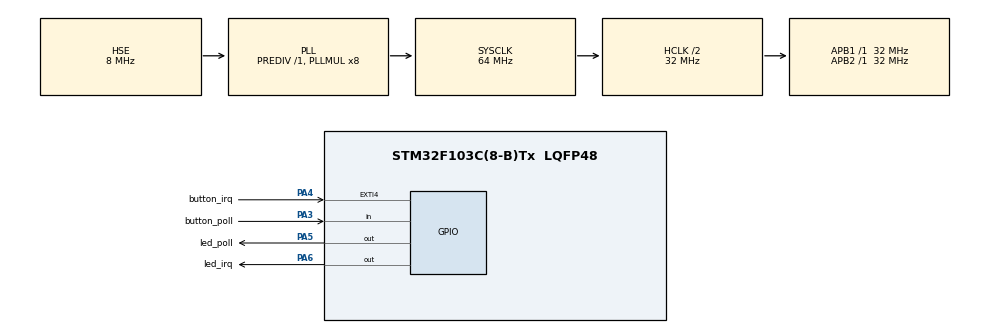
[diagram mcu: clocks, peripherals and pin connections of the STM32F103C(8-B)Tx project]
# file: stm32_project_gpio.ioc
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Mcu.Family=STM32F1
Mcu.Name=STM32F103C(8-B)Tx
Mcu.Package=LQFP48
NVIC.EXTI4_IRQn=true\:0\:0\:false\:false\:true\:true\:true
NVIC.PriorityGroup=NVIC_PRIORITYGROUP_4
PA13.Mode=Serial_Wire
PA13.Signal=SYS_JTMS-SWDIO
PA14.Mode=Serial_Wire
PA14.Signal=SYS_JTCK-SWCLK
PA3.GPIO_Label=button_poll
PA3.Signal=GPIO_Input
PA4.GPIO_Label=button_irq
PA4.GPIO_ModeDefaultEXTI=GPIO_MODE_IT_FALLING
PA4.Signal=GPXTI4
PA5.GPIO_Label=led_poll
PA5.Signal=GPIO_Output
PA6.GPIO_Label=led_irq
PA6.Signal=GPIO_Output
PD0-OSC_IN.Mode=HSE-External-Oscillator
PD0-OSC_IN.Signal=RCC_OSC_IN
PD1-OSC_OUT.Mode=HSE-External-Oscillator
PD1-OSC_OUT.Signal=RCC_OSC_OUT
ProjectManager.HeapSize=0x200
ProjectManager.StackSize=0x400
ProjectManager.TargetToolchain=Makefile
RCC.AHBCLKDivider=RCC_SYSCLK_DIV2
RCC.AHBFreq_Value=32000000
RCC.APB1Freq_Value=32000000
RCC.APB1TimFreq_Value=32000000
RCC.APB2Freq_Value=32000000
RCC.APB2TimFreq_Value=32000000
RCC.HCLKFreq_Value=32000000
RCC.PLLMUL=RCC_PLL_MUL8
RCC.PLLSourceVirtual=RCC_PLLSOURCE_HSE
RCC.SYSCLKFreq_VALUE=64000000
RCC.SYSCLKSource=RCC_SYSCLKSOURCE_PLLCLK
RCC.USBFreq_Value=64000000
board=custom

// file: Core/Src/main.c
/* USER CODE BEGIN Header */
/**
  ******************************************************************************
  * @file           : main.c
  * @brief          : Main program body
  ******************************************************************************
  * @attention
  *
  * <h2><center>&copy; Copyright (c) 2023 STMicroelectronics.
  * All rights reserved.</center></h2>
  *
  * This software component is licensed by ST under BSD 3-Clause license,
  * the "License"; You may not use this file except in compliance with the
  * License. You may obtain a copy of the License at:
  *                        opensource.org/licenses/BSD-3-Clause
  *
  ******************************************************************************
  */
/* USER CODE END Header */
#include "main.h"

void SystemClock_Config(void);
static void MX_GPIO_Init(void);

/* USER CODE BEGIN 0 */
int interrupted;
/* USER CODE END 0 */

int main(void)
{

  /* MCU Configuration--------------------------------------------------------*/

  /* Reset of all peripherals, Initializes the Flash interface and the Systick. */
  HAL_Init();

  /* Configure the system clock */
  SystemClock_Config();

  /* Initialize all configured peripherals */
  MX_GPIO_Init();

  /* Infinite loop */
  /* USER CODE BEGIN WHILE */
  interrupted = 0;
  while (1)
  {
    GPIO_PinState state = HAL_GPIO_ReadPin(button_poll_GPIO_Port, button_poll_Pin);
    HAL_GPIO_WritePin(led_poll_GPIO_Port, led_poll_Pin, state);

    if (interrupted) {
      interrupted = 0;
      HAL_NVIC_EnableIRQ(EXTI4_IRQn);
      HAL_GPIO_TogglePin(led_irq_GPIO_Port, led_irq_Pin);
    }
    /* USER CODE END WHILE */

  }
}

void SystemClock_Config(void)
{
  RCC_OscInitTypeDef RCC_OscInitStruct = {0};
  RCC_ClkInitTypeDef RCC_ClkInitStruct = {0};

  /** Initializes the RCC Oscillators according to the specified parameters
  * in the RCC_OscInitTypeDef structure.
  */
  RCC_OscInitStruct.OscillatorType = RCC_OSCILLATORTYPE_HSE;
  RCC_OscInitStruct.HSEState = RCC_HSE_ON;
  RCC_OscInitStruct.HSEPredivValue = RCC_HSE_PREDIV_DIV1;
  RCC_OscInitStruct.HSIState = RCC_HSI_ON;
  RCC_OscInitStruct.PLL.PLLState = RCC_PLL_ON;
  RCC_OscInitStruct.PLL.PLLSource = RCC_PLLSOURCE_HSE;
  RCC_OscInitStruct.PLL.PLLMUL = RCC_PLL_MUL8;
  if (HAL_RCC_OscConfig(&RCC_OscInitStruct) != HAL_OK)
  {
    Error_Handler();
  }
  /** Initializes the CPU, AHB and APB buses clocks
  */
  RCC_ClkInitStruct.ClockType = RCC_CLOCKTYPE_HCLK|RCC_CLOCKTYPE_SYSCLK
                              |RCC_CLOCKTYPE_PCLK1|RCC_CLOCKTYPE_PCLK2;
  RCC_ClkInitStruct.SYSCLKSource = RCC_SYSCLKSOURCE_PLLCLK;
  RCC_ClkInitStruct.AHBCLKDivider = RCC_SYSCLK_DIV2;
  RCC_ClkInitStruct.APB1CLKDivider = RCC_HCLK_DIV1;
  RCC_ClkInitStruct.APB2CLKDivider = RCC_HCLK_DIV1;

  if (HAL_RCC_ClockConfig(&RCC_ClkInitStruct, FLASH_LATENCY_2) != HAL_OK)
  {
    Error_Handler();
  }
}

static void MX_GPIO_Init(void)
{
  GPIO_InitTypeDef GPIO_InitStruct = {0};

  /* GPIO Ports Clock Enable */
  __HAL_RCC_GPIOD_CLK_ENABLE();
  __HAL_RCC_GPIOA_CLK_ENABLE();

  /*Configure GPIO pin Output Level */
  HAL_GPIO_WritePin(GPIOA, led_poll_Pin|led_irq_Pin, GPIO_PIN_RESET);

  /*Configure GPIO pin : button_poll_Pin */
  GPIO_InitStruct.Pin = button_poll_Pin;
  GPIO_InitStruct.Mode = GPIO_MODE_INPUT;
  GPIO_InitStruct.Pull = GPIO_NOPULL;
  HAL_GPIO_Init(button_poll_GPIO_Port, &GPIO_InitStruct);

  /*Configure GPIO pin : button_irq_Pin */
  GPIO_InitStruct.Pin = button_irq_Pin;
  GPIO_InitStruct.Mode = GPIO_MODE_IT_FALLING;
  GPIO_InitStruct.Pull = GPIO_NOPULL;
  HAL_GPIO_Init(button_irq_GPIO_Port, &GPIO_InitStruct);

  /*Configure GPIO pins : led_poll_Pin led_irq_Pin */
  GPIO_InitStruct.Pin = led_poll_Pin|led_irq_Pin;
  GPIO_InitStruct.Mode = GPIO_MODE_OUTPUT_PP;
  GPIO_InitStruct.Pull = GPIO_NOPULL;
  GPIO_InitStruct.Speed = GPIO_SPEED_FREQ_LOW;
  HAL_GPIO_Init(GPIOA, &GPIO_InitStruct);

  /* EXTI interrupt init*/
  HAL_NVIC_SetPriority(EXTI4_IRQn, 0, 0);
  HAL_NVIC_EnableIRQ(EXTI4_IRQn);

}

/* USER CODE BEGIN 4 */

void HAL_GPIO_EXTI_Callback(uint16_t GPIO_Pin)
{
  if (GPIO_Pin != button_irq_Pin) return;
  interrupted = 1;
  HAL_NVIC_DisableIRQ(EXTI4_IRQn);
}
/* USER CODE END 4 */

void Error_Handler(void)
{
  __disable_irq();
  while (1)
  {
  }
}

/************************ (C) COPYRIGHT STMicroelectronics *****END OF FILE****/
